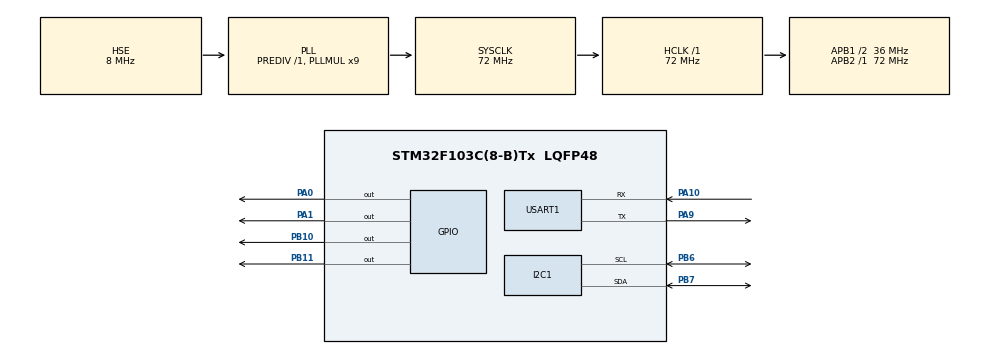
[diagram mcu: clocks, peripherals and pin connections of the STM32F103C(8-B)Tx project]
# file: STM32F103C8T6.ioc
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I2C1.I2C_Mode=I2C_Fast
Mcu.Family=STM32F1
Mcu.Name=STM32F103C(8-B)Tx
Mcu.Package=LQFP48
NVIC.PriorityGroup=NVIC_PRIORITYGROUP_4
NVIC.TIM2_IRQn=true\:0\:0\:false\:false\:true\:true\:true\:true
PA0-WKUP.GPIO_PuPd=GPIO_PULLUP
PA0-WKUP.GPIO_Speed=GPIO_SPEED_FREQ_HIGH
PA0-WKUP.Signal=GPIO_Output
PA1.GPIO_PuPd=GPIO_PULLUP
PA1.GPIO_Speed=GPIO_SPEED_FREQ_HIGH
PA1.Signal=GPIO_Output
PA10.Mode=Asynchronous
PA10.Signal=USART1_RX
PA13.Mode=Serial_Wire
PA13.Signal=SYS_JTMS-SWDIO
PA14.Mode=Serial_Wire
PA14.Signal=SYS_JTCK-SWCLK
PA9.Mode=Asynchronous
PA9.Signal=USART1_TX
PB10.GPIO_Speed=GPIO_SPEED_FREQ_HIGH
PB10.Signal=GPIO_Output
PB11.GPIO_Speed=GPIO_SPEED_FREQ_HIGH
PB11.Signal=GPIO_Output
PB6.Mode=I2C
PB6.Signal=I2C1_SCL
PB7.Mode=I2C
PB7.Signal=I2C1_SDA
PD0-OSC_IN.Mode=HSE-External-Oscillator
PD0-OSC_IN.Signal=RCC_OSC_IN
PD1-OSC_OUT.Mode=HSE-External-Oscillator
PD1-OSC_OUT.Signal=RCC_OSC_OUT
ProjectManager.HeapSize=0x200
ProjectManager.StackSize=0x400
ProjectManager.TargetToolchain=STM32CubeIDE
RCC.AHBFreq_Value=72000000
RCC.APB1CLKDivider=RCC_HCLK_DIV2
RCC.APB1Freq_Value=36000000
RCC.APB1TimFreq_Value=72000000
RCC.APB2Freq_Value=72000000
RCC.APB2TimFreq_Value=72000000
RCC.HCLKFreq_Value=72000000
RCC.PLLMUL=RCC_PLL_MUL9
RCC.PLLSourceVirtual=RCC_PLLSOURCE_HSE
RCC.SYSCLKFreq_VALUE=72000000
RCC.SYSCLKSource=RCC_SYSCLKSOURCE_PLLCLK
RCC.USBFreq_Value=72000000
TIM2.AutoReloadPreload=TIM_AUTORELOAD_PRELOAD_ENABLE
TIM2.Period=5000 - 1
TIM2.Prescaler=72-1
USART1.VirtualMode=VM_ASYNC
VP_TIM2_VS_ClockSourceINT.Mode=Internal
board=custom

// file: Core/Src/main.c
/* USER CODE BEGIN Header */
/**
  ******************************************************************************
  * @file           : main.c
  * @brief          : Main program body
  ******************************************************************************
  * @attention
  *
  * Copyright (c) 2025 STMicroelectronics.
  * All rights reserved.
  *
  * This software is licensed under terms that can be found in the LICENSE file
  * in the root directory of this software component.
  * If no LICENSE file comes with this software, it is provided AS-IS.
  *
  ******************************************************************************
  */
/* USER CODE END Header */
#include "main.h"
#include "i2c.h"
#include "tim.h"
#include "usart.h"
#include "gpio.h"

/* USER CODE BEGIN Includes */
#include "HAl_Add.h"
#include "MPU6050.h"
#include "OLED.h"
/* USER CODE END Includes */

/* USER CODE BEGIN PM */

/*/////////////////////硬件连接/////////////////////
OLED屏幕      SCL B10    SDA  B11
MPU6050       SCL B6     SDA  B7
USART(串口)	   TX  A9    RX  A10
*//////////////////////硬件连接/////////////////////

/* USER CODE END PM */

/* USER CODE BEGIN PV */
MPU6050 MM;
/* USER CODE END PV */

void SystemClock_Config(void);
/* USER CODE BEGIN PFP */
void HAL_TIM_PeriodElapsedCallback(TIM_HandleTypeDef *htim)
{
  if (htim->Instance == TIM2)
  {
	  MPU6050_Get_Angle(&MM);//(超低零点漂移)
	  //MPU6050_Get_Angle_Plus(&MM);//四元素法
  }
}

/* USER CODE END PFP */

int main(void)
{

  /* MCU Configuration--------------------------------------------------------*/

  /* Reset of all peripherals, Initializes the Flash interface and the Systick. */
  HAL_Init();

  /* Configure the system clock */
  SystemClock_Config();

  /* Initialize all configured peripherals */
  MX_GPIO_Init();
  MX_I2C1_Init();
  MX_TIM2_Init();
  MX_USART1_UART_Init();
  /* USER CODE BEGIN 2 */
  OLED_Init(GPIOB,GPIO_PIN_11,GPIO_PIN_10,1);//如果是0.96寸屏幕，后面就写1，否则就是0
  MPU6050_init(&hi2c1);//初始化MPU6050(你使用的硬件iic)
  HAL_TIM_Base_Start_IT(&htim2);//定时器中断(确保每次读取的dt稳定)
  /* USER CODE END 2 */

  /* Infinite loop */
  /* USER CODE BEGIN WHILE */
  while (1)
  {

	  /*显示屏操作
	  OLED_Clear();
	  OLED_Printf(0,0,6,"pitch:%.2f",MM.pitch);
	  OLED_Printf(0,8,6,"roll:%.2f",MM.roll);
	  OLED_Printf(0,16,6,"yaw:%.2f",MM.yaw);
	  OLED_Update();
	  */

	  //串口操作
	  printf("%.3f,%.3f,%.3f\n",MM.roll,MM.pitch,MM.yaw);//欧拉角描述
//	  printf("%.2f,%.2f,%.2f,%.2f\n",MM.q0,MM.q1,MM.q2,MM.q3);//四元数描述法

//	  printf("ID:%x",MPU6050_ID()); // 打印MPU6050的ID用于检车与设备连接是否正常

    /* USER CODE END WHILE */

  }
}

void SystemClock_Config(void)
{
  RCC_OscInitTypeDef RCC_OscInitStruct = {0};
  RCC_ClkInitTypeDef RCC_ClkInitStruct = {0};

  /** Initializes the RCC Oscillators according to the specified parameters
  * in the RCC_OscInitTypeDef structure.
  */
  RCC_OscInitStruct.OscillatorType = RCC_OSCILLATORTYPE_HSE;
  RCC_OscInitStruct.HSEState = RCC_HSE_ON;
  RCC_OscInitStruct.HSEPredivValue = RCC_HSE_PREDIV_DIV1;
  RCC_OscInitStruct.HSIState = RCC_HSI_ON;
  RCC_OscInitStruct.PLL.PLLState = RCC_PLL_ON;
  RCC_OscInitStruct.PLL.PLLSource = RCC_PLLSOURCE_HSE;
  RCC_OscInitStruct.PLL.PLLMUL = RCC_PLL_MUL9;
  if (HAL_RCC_OscConfig(&RCC_OscInitStruct) != HAL_OK)
  {
    Error_Handler();
  }

  /** Initializes the CPU, AHB and APB buses clocks
  */
  RCC_ClkInitStruct.ClockType = RCC_CLOCKTYPE_HCLK|RCC_CLOCKTYPE_SYSCLK
                              |RCC_CLOCKTYPE_PCLK1|RCC_CLOCKTYPE_PCLK2;
  RCC_ClkInitStruct.SYSCLKSource = RCC_SYSCLKSOURCE_PLLCLK;
  RCC_ClkInitStruct.AHBCLKDivider = RCC_SYSCLK_DIV1;
  RCC_ClkInitStruct.APB1CLKDivider = RCC_HCLK_DIV2;
  RCC_ClkInitStruct.APB2CLKDivider = RCC_HCLK_DIV1;

  if (HAL_RCC_ClockConfig(&RCC_ClkInitStruct, FLASH_LATENCY_2) != HAL_OK)
  {
    Error_Handler();
  }
}

void Error_Handler(void)
{
  __disable_irq();
  while (1)
  {
  }
}
